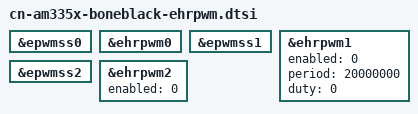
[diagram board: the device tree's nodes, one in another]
/*
 * Modified PWM Solution for Carpe Noctem Cassel
 * 
 * This Modification should enable PWM for Ti-Kernel 4.4.x
 */

&epwmss0 {
        status = "okay";
};

&ehrpwm0 {
        status = "okay";
};

&epwmss1 {
        status = "okay";
};

&ehrpwm1 {
        enabled = <0>;
        period = <20000000>;
        duty   = <0>;
        status = "okay";
};

&epwmss2 {
        status = "okay";
};

&ehrpwm2 {
        enabled = <0>;
        status = "okay";
};

